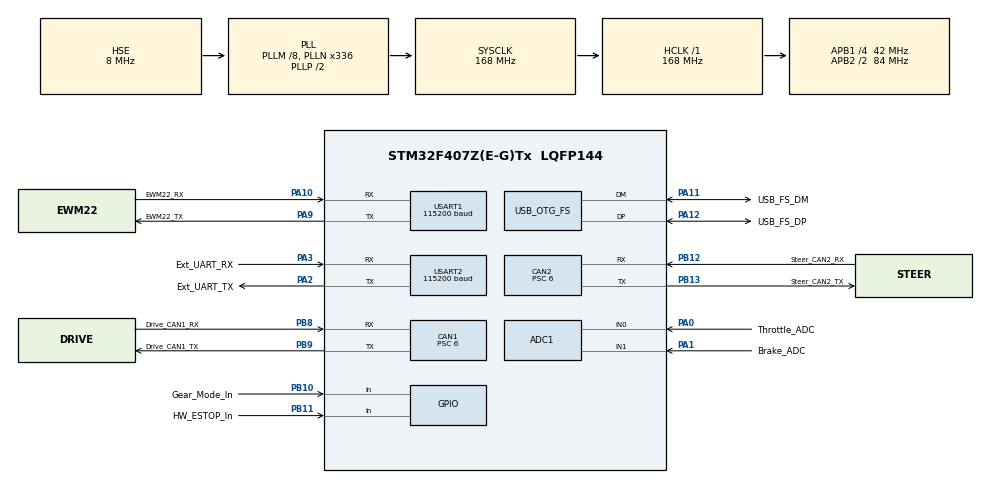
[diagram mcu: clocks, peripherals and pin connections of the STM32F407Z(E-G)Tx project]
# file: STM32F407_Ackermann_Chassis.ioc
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ADC1.Channel-0\#ChannelRegularConversion=ADC_CHANNEL_0
ADC1.Channel-1\#ChannelRegularConversion=ADC_CHANNEL_1
ADC1.EOCSelection=ADC_EOC_SINGLE_CONV
ADC1.NbrOfConversion=2
ADC1.NbrOfConversionFlag=1
ADC1.Rank-0\#ChannelRegularConversion=1
ADC1.Rank-1\#ChannelRegularConversion=2
ADC1.SamplingTime-0\#ChannelRegularConversion=ADC_SAMPLETIME_3CYCLES
ADC1.SamplingTime-1\#ChannelRegularConversion=ADC_SAMPLETIME_3CYCLES
ADC1.ScanConvMode=ENABLE
ADC1.master=1
CAN1.BS1=CAN_BS1_12TQ
CAN1.CalculateBaudRate=500000
CAN1.CalculateTimeBit=2000
CAN1.CalculateTimeQuantum=142.85714285714286
CAN1.Prescaler=6
CAN2.BS1=CAN_BS1_12TQ
CAN2.CalculateBaudRate=500000
CAN2.CalculateTimeBit=2000
CAN2.CalculateTimeQuantum=142.85714285714286
CAN2.Prescaler=6
Mcu.Family=STM32F4
Mcu.Name=STM32F407Z(E-G)Tx
Mcu.Package=LQFP144
NVIC.OTG_FS_IRQn=true\:0\:0\:false\:false\:true\:false\:true\:true
NVIC.PriorityGroup=NVIC_PRIORITYGROUP_4
PA0-WKUP.GPIO_Label=Throttle_ADC
PA0-WKUP.Signal=ADCx_IN0
PA1.GPIO_Label=Brake_ADC
PA1.Signal=ADCx_IN1
PA10.GPIO_Label=EWM22_RX
PA10.Mode=Asynchronous
PA10.Signal=USART1_RX
PA11.GPIO_Label=USB_FS_DM
PA11.Mode=Device_Only
PA11.Signal=USB_OTG_FS_DM
PA12.GPIO_Label=USB_FS_DP
PA12.Mode=Device_Only
PA12.Signal=USB_OTG_FS_DP
PA13.Mode=Serial_Wire
PA13.Signal=SYS_JTMS-SWDIO
PA14.Mode=Serial_Wire
PA14.Signal=SYS_JTCK-SWCLK
PA2.GPIO_Label=Ext_UART_TX
PA2.Mode=Asynchronous
PA2.Signal=USART2_TX
PA3.GPIO_Label=Ext_UART_RX
PA3.Mode=Asynchronous
PA3.Signal=USART2_RX
PA9.GPIO_Label=EWM22_TX
PA9.Mode=Asynchronous
PA9.Signal=USART1_TX
PB10.GPIO_Label=Gear_Mode_In
PB10.GPIO_PuPd=GPIO_PULLDOWN
PB10.Signal=GPIO_Input
PB11.GPIO_Label=HW_ESTOP_In
PB11.GPIO_PuPd=GPIO_PULLDOWN
PB11.Signal=GPIO_Input
PB12.GPIO_Label=Steer_CAN2_RX
PB12.Mode=CAN_Activate
PB12.Signal=CAN2_RX
PB13.GPIO_Label=Steer_CAN2_TX
PB13.Mode=CAN_Activate
PB13.Signal=CAN2_TX
PB8.GPIO_Label=Drive_CAN1_RX
PB8.Mode=CAN_Activate
PB8.Signal=CAN1_RX
PB9.GPIO_Label=Drive_CAN1_TX
PB9.Mode=CAN_Activate
PB9.Signal=CAN1_TX
PH0-OSC_IN.Mode=HSE-External-Oscillator
PH0-OSC_IN.Signal=RCC_OSC_IN
PH1-OSC_OUT.Mode=HSE-External-Oscillator
PH1-OSC_OUT.Signal=RCC_OSC_OUT
ProjectManager.HeapSize=0x200
ProjectManager.StackSize=0x400
ProjectManager.TargetToolchain=STM32CubeIDE
RCC.48MHZClocksFreq_Value=48000000
RCC.AHBFreq_Value=168000000
RCC.APB1CLKDivider=RCC_HCLK_DIV4
RCC.APB1Freq_Value=42000000
RCC.APB1TimFreq_Value=84000000
RCC.APB2CLKDivider=RCC_HCLK_DIV2
RCC.APB2Freq_Value=84000000
RCC.APB2TimFreq_Value=168000000
RCC.CortexFreq_Value=168000000
RCC.HCLKFreq_Value=168000000
RCC.HSE_VALUE=8000000
RCC.HSI_VALUE=16000000
RCC.LSE_VALUE=32768
RCC.PLLM=8
RCC.PLLN=336
RCC.PLLQ=7
RCC.SYSCLKFreq_VALUE=168000000
RCC.SYSCLKSource=RCC_SYSCLKSOURCE_PLLCLK
RCC.VCOOutputFreq_Value=336000000
SH.ADCx_IN0.0=ADC1_IN0,IN0
SH.ADCx_IN1.0=ADC1_IN1,IN1
USART1.BaudRate=115200
USART1.VirtualMode=VM_ASYNC
USART2.BaudRate=115200
USART2.VirtualMode=VM_ASYNC
USB_DEVICE.CLASS_NAME_FS=CDC
USB_DEVICE.VirtualMode-CDC_FS=Cdc
USB_DEVICE.VirtualModeFS=Cdc_FS
USB_OTG_FS.VirtualMode=Device_Only
VP_USB_DEVICE_VS_USB_DEVICE_CDC_FS.Mode=CDC_FS
board=custom

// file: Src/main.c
/* USER CODE BEGIN Header */
/**
  ******************************************************************************
  * @file           : main.c
  * @brief          : Main program body
  ******************************************************************************
  * @attention
  *
  * Copyright (c) 2026 STMicroelectronics.
  * All rights reserved.
  *
  * This software is licensed under terms that can be found in the LICENSE file
  * in the root directory of this software component.
  * If no LICENSE file comes with this software, it is provided AS-IS.
  *
  ******************************************************************************
  */
/* USER CODE END Header */
#include "main.h"
#include "usb_device.h"

/* USER CODE BEGIN Includes */
#include "chassis_app.h"

/* USER CODE END Includes */

ADC_HandleTypeDef hadc1;

CAN_HandleTypeDef hcan1;
CAN_HandleTypeDef hcan2;

UART_HandleTypeDef huart1;
UART_HandleTypeDef huart2;

void SystemClock_Config(void);
static void MX_GPIO_Init(void);
static void MX_ADC1_Init(void);
static void MX_CAN1_Init(void);
static void MX_CAN2_Init(void);
static void MX_USART1_UART_Init(void);
static void MX_USART2_UART_Init(void);

int main(void)
{

  /* MCU Configuration--------------------------------------------------------*/

  /* Reset of all peripherals, Initializes the Flash interface and the Systick. */
  HAL_Init();

  /* Configure the system clock */
  SystemClock_Config();

  /* Initialize all configured peripherals */
  MX_GPIO_Init();
  MX_ADC1_Init();
  MX_CAN1_Init();
  MX_CAN2_Init();
  MX_USART1_UART_Init();
  MX_USART2_UART_Init();
  MX_USB_DEVICE_Init();
  /* USER CODE BEGIN 2 */
  chassis_app_init(&hadc1, &hcan1, &hcan2, &huart1);

  /* USER CODE END 2 */

  /* Infinite loop */
  while (1)
  {

    /* USER CODE BEGIN 3 */
    chassis_app_process();
  }
  /* USER CODE END 3 */
}

void SystemClock_Config(void)
{
  RCC_OscInitTypeDef RCC_OscInitStruct = {0};
  RCC_ClkInitTypeDef RCC_ClkInitStruct = {0};

  /** Configure the main internal regulator output voltage
  */
  __HAL_RCC_PWR_CLK_ENABLE();
  __HAL_PWR_VOLTAGESCALING_CONFIG(PWR_REGULATOR_VOLTAGE_SCALE1);

  /** Initializes the RCC Oscillators according to the specified parameters
  * in the RCC_OscInitTypeDef structure.
  */
  RCC_OscInitStruct.OscillatorType = RCC_OSCILLATORTYPE_HSE;
  RCC_OscInitStruct.HSEState = RCC_HSE_ON;
  RCC_OscInitStruct.PLL.PLLState = RCC_PLL_ON;
  RCC_OscInitStruct.PLL.PLLSource = RCC_PLLSOURCE_HSE;
  RCC_OscInitStruct.PLL.PLLM = 8;
  RCC_OscInitStruct.PLL.PLLN = 336;
  RCC_OscInitStruct.PLL.PLLP = RCC_PLLP_DIV2;
  RCC_OscInitStruct.PLL.PLLQ = 7;
  if (HAL_RCC_OscConfig(&RCC_OscInitStruct) != HAL_OK)
  {
    Error_Handler();
  }

  /** Initializes the CPU, AHB and APB buses clocks
  */
  RCC_ClkInitStruct.ClockType = RCC_CLOCKTYPE_HCLK|RCC_CLOCKTYPE_SYSCLK
                              |RCC_CLOCKTYPE_PCLK1|RCC_CLOCKTYPE_PCLK2;
  RCC_ClkInitStruct.SYSCLKSource = RCC_SYSCLKSOURCE_PLLCLK;
  RCC_ClkInitStruct.AHBCLKDivider = RCC_SYSCLK_DIV1;
  RCC_ClkInitStruct.APB1CLKDivider = RCC_HCLK_DIV4;
  RCC_ClkInitStruct.APB2CLKDivider = RCC_HCLK_DIV2;

  if (HAL_RCC_ClockConfig(&RCC_ClkInitStruct, FLASH_LATENCY_5) != HAL_OK)
  {
    Error_Handler();
  }
}

static void MX_ADC1_Init(void)
{

  ADC_ChannelConfTypeDef sConfig = {0};

  /** Configure the global features of the ADC (Clock, Resolution, Data Alignment and number of conversion)
  */
  hadc1.Instance = ADC1;
  hadc1.Init.ClockPrescaler = ADC_CLOCK_SYNC_PCLK_DIV4;
  hadc1.Init.Resolution = ADC_RESOLUTION_12B;
  hadc1.Init.ScanConvMode = DISABLE;
  hadc1.Init.ContinuousConvMode = DISABLE;
  hadc1.Init.DiscontinuousConvMode = DISABLE;
  hadc1.Init.ExternalTrigConvEdge = ADC_EXTERNALTRIGCONVEDGE_NONE;
  hadc1.Init.ExternalTrigConv = ADC_SOFTWARE_START;
  hadc1.Init.DataAlign = ADC_DATAALIGN_RIGHT;
  hadc1.Init.NbrOfConversion = 1;
  hadc1.Init.DMAContinuousRequests = DISABLE;
  hadc1.Init.EOCSelection = ADC_EOC_SINGLE_CONV;
  if (HAL_ADC_Init(&hadc1) != HAL_OK)
  {
    Error_Handler();
  }

  /** Configure for the selected ADC regular channel its corresponding rank in the sequencer and its sample time.
  */
  sConfig.Channel = ADC_CHANNEL_0;
  sConfig.Rank = 1;
  sConfig.SamplingTime = ADC_SAMPLETIME_144CYCLES;
  if (HAL_ADC_ConfigChannel(&hadc1, &sConfig) != HAL_OK)
  {
    Error_Handler();
  }

}

static void MX_CAN1_Init(void)
{

  hcan1.Instance = CAN1;
  hcan1.Init.Prescaler = 6;
  hcan1.Init.Mode = CAN_MODE_NORMAL;
  hcan1.Init.SyncJumpWidth = CAN_SJW_1TQ;
  hcan1.Init.TimeSeg1 = CAN_BS1_12TQ;
  hcan1.Init.TimeSeg2 = CAN_BS2_1TQ;
  hcan1.Init.TimeTriggeredMode = DISABLE;
  hcan1.Init.AutoBusOff = ENABLE;
  hcan1.Init.AutoWakeUp = DISABLE;
  hcan1.Init.AutoRetransmission = DISABLE;
  hcan1.Init.ReceiveFifoLocked = DISABLE;
  hcan1.Init.TransmitFifoPriority = DISABLE;
  if (HAL_CAN_Init(&hcan1) != HAL_OK)
  {
    Error_Handler();
  }

}

static void MX_CAN2_Init(void)
{

  hcan2.Instance = CAN2;
  hcan2.Init.Prescaler = 6;
  hcan2.Init.Mode = CAN_MODE_NORMAL;
  hcan2.Init.SyncJumpWidth = CAN_SJW_1TQ;
  hcan2.Init.TimeSeg1 = CAN_BS1_12TQ;
  hcan2.Init.TimeSeg2 = CAN_BS2_1TQ;
  hcan2.Init.TimeTriggeredMode = DISABLE;
  hcan2.Init.AutoBusOff = ENABLE;
  hcan2.Init.AutoWakeUp = DISABLE;
  hcan2.Init.AutoRetransmission = DISABLE;
  hcan2.Init.ReceiveFifoLocked = DISABLE;
  hcan2.Init.TransmitFifoPriority = DISABLE;
  if (HAL_CAN_Init(&hcan2) != HAL_OK)
  {
    Error_Handler();
  }

}

static void MX_USART1_UART_Init(void)
{

  huart1.Instance = USART1;
  huart1.Init.BaudRate = 115200;
  huart1.Init.WordLength = UART_WORDLENGTH_8B;
  huart1.Init.StopBits = UART_STOPBITS_1;
  huart1.Init.Parity = UART_PARITY_NONE;
  huart1.Init.Mode = UART_MODE_TX_RX;
  huart1.Init.HwFlowCtl = UART_HWCONTROL_NONE;
  huart1.Init.OverSampling = UART_OVERSAMPLING_16;
  if (HAL_UART_Init(&huart1) != HAL_OK)
  {
    Error_Handler();
  }

}

static void MX_USART2_UART_Init(void)
{

  huart2.Instance = USART2;
  huart2.Init.BaudRate = 115200;
  huart2.Init.WordLength = UART_WORDLENGTH_8B;
  huart2.Init.StopBits = UART_STOPBITS_1;
  huart2.Init.Parity = UART_PARITY_NONE;
  huart2.Init.Mode = UART_MODE_TX_RX;
  huart2.Init.HwFlowCtl = UART_HWCONTROL_NONE;
  huart2.Init.OverSampling = UART_OVERSAMPLING_16;
  if (HAL_UART_Init(&huart2) != HAL_OK)
  {
    Error_Handler();
  }

}

static void MX_GPIO_Init(void)
{
  GPIO_InitTypeDef GPIO_InitStruct = {0};

  /* GPIO Ports Clock Enable */
  __HAL_RCC_GPIOH_CLK_ENABLE();
  __HAL_RCC_GPIOA_CLK_ENABLE();
  __HAL_RCC_GPIOB_CLK_ENABLE();

  /*Configure GPIO pin : Gear_Mode_In_Pin */
  GPIO_InitStruct.Pin = Gear_Mode_In_Pin;
  GPIO_InitStruct.Mode = GPIO_MODE_INPUT;
  GPIO_InitStruct.Pull = GPIO_PULLDOWN;
  HAL_GPIO_Init(Gear_Mode_In_GPIO_Port, &GPIO_InitStruct);

  /*Configure GPIO pin : HW_ESTOP_In_Pin */
  GPIO_InitStruct.Pin = HW_ESTOP_In_Pin;
  GPIO_InitStruct.Mode = GPIO_MODE_INPUT;
  GPIO_InitStruct.Pull = GPIO_PULLDOWN;
  HAL_GPIO_Init(HW_ESTOP_In_GPIO_Port, &GPIO_InitStruct);

}

void Error_Handler(void)
{
  __disable_irq();
  while (1)
  {
  }
}
